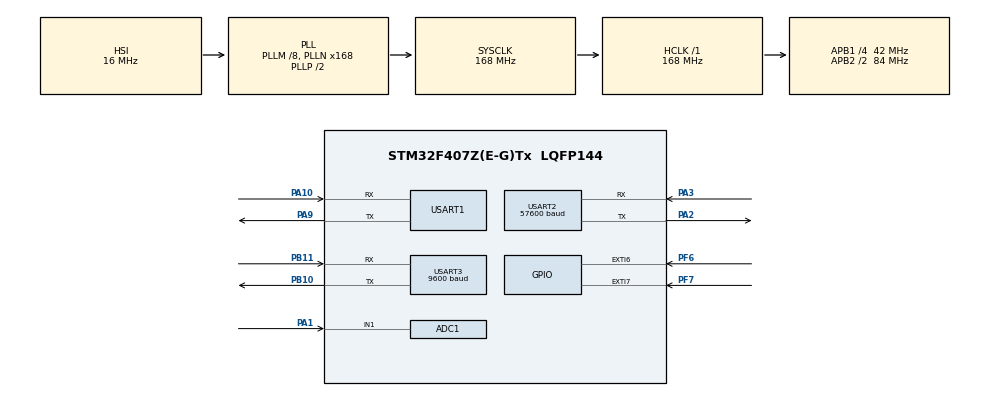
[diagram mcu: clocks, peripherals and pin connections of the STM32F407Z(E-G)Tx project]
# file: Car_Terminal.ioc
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ADC1.Channel-0\#ChannelRegularConversion=ADC_CHANNEL_1
ADC1.ClockPrescaler=ADC_CLOCK_SYNC_PCLK_DIV6
ADC1.NbrOfConversionFlag=1
ADC1.Rank-0\#ChannelRegularConversion=1
ADC1.SamplingTime-0\#ChannelRegularConversion=ADC_SAMPLETIME_3CYCLES
ADC1.master=1
Mcu.Family=STM32F4
Mcu.Name=STM32F407Z(E-G)Tx
Mcu.Package=LQFP144
NVIC.EXTI9_5_IRQn=true\:1\:0\:true\:false\:true\:true\:true\:true
NVIC.PriorityGroup=NVIC_PRIORITYGROUP_4
NVIC.RCC_IRQn=true\:0\:0\:false\:false\:true\:true\:false\:true
NVIC.TIM2_IRQn=true\:14\:0\:true\:false\:true\:true\:true\:true
PA1.Signal=ADCx_IN1
PA10.Mode=Asynchronous
PA10.Signal=USART1_RX
PA2.Mode=Asynchronous
PA2.Signal=USART2_TX
PA3.Mode=Asynchronous
PA3.Signal=USART2_RX
PA9.Mode=Asynchronous
PA9.Signal=USART1_TX
PB10.Mode=Asynchronous
PB10.Signal=USART3_TX
PB11.Mode=Asynchronous
PB11.Signal=USART3_RX
PF6.GPIO_ModeDefaultEXTI=GPIO_MODE_IT_FALLING
PF6.GPIO_PuPd=GPIO_PULLUP
PF6.Signal=GPXTI6
PF7.GPIO_ModeDefaultEXTI=GPIO_MODE_IT_RISING
PF7.GPIO_PuPd=GPIO_PULLDOWN
PF7.Signal=GPXTI7
ProjectManager.HeapSize=0x200
ProjectManager.StackSize=0x400
ProjectManager.TargetToolchain=MDK-ARM V5
RCC.48MHZClocksFreq_Value=84000000
RCC.AHBFreq_Value=168000000
RCC.APB1CLKDivider=RCC_HCLK_DIV4
RCC.APB1Freq_Value=42000000
RCC.APB1TimFreq_Value=84000000
RCC.APB2CLKDivider=RCC_HCLK_DIV2
RCC.APB2Freq_Value=84000000
RCC.APB2TimFreq_Value=168000000
RCC.CortexFreq_Value=168000000
RCC.HCLKFreq_Value=168000000
RCC.HSE_VALUE=25000000
RCC.HSI_VALUE=16000000
RCC.LSE_VALUE=32768
RCC.PLLM=8
RCC.PLLN=168
RCC.SYSCLKFreq_VALUE=168000000
RCC.SYSCLKSource=RCC_SYSCLKSOURCE_PLLCLK
RCC.VCOOutputFreq_Value=336000000
SH.ADCx_IN1.0=ADC1_IN1,IN1
TIM2.AutoReloadPreload=TIM_AUTORELOAD_PRELOAD_ENABLE
TIM2.ClockDivision=TIM_CLOCKDIVISION_DIV4
TIM2.CounterMode=TIM_COUNTERMODE_DOWN
TIM2.Period=2000
TIM2.Prescaler=42000
USART1.VirtualMode=VM_ASYNC
USART2.BaudRate=57600
USART2.VirtualMode=VM_ASYNC
USART3.BaudRate=9600
USART3.VirtualMode=VM_ASYNC
VP_TIM2_VS_ClockSourceINT.Mode=Internal
board=custom

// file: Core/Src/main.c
/* USER CODE BEGIN Header */
/**
  ******************************************************************************
  * @file           : main.c
  * @brief          : Main program body
  ******************************************************************************
  * @attention
  *
  * Copyright (c) 2024 STMicroelectronics.
  * All rights reserved.
  *
  * This software is licensed under terms that can be found in the LICENSE file
  * in the root directory of this software component.
  * If no LICENSE file comes with this software, it is provided AS-IS.
  *
  ******************************************************************************
  */
/* USER CODE END Header */
#include "main.h"
#include "adc.h"
#include "tim.h"
#include "usart.h"
#include "gpio.h"

/* USER CODE BEGIN Includes */
#include "MyCallbackFunc.h"
#include "string.h"
#include "AS608.h"
#include "AES128.h"
#include "syn6288.h"
/* USER CODE END Includes */

void SystemClock_Config(void);

/* USER CODE BEGIN 0 */

uint8_t SYN_StopCom[] = {0xFD, 0X00, 0X02, 0X02, 0XFD}; //停止合成
uint8_t SYN_SuspendCom[] = {0XFD, 0X00, 0X02, 0X03, 0XFC}; //暂停合成
uint8_t SYN_RecoverCom[] = {0XFD, 0X00, 0X02, 0X04, 0XFB}; //恢复合成
uint8_t SYN_ChackCom[] = {0XFD, 0X00, 0X02, 0X21, 0XDE}; //状濁查诿
uint8_t SYN_PowerDownCom[] = {0XFD, 0X00, 0X02, 0X88, 0X77}; //进入POWER DOWN 状濁命仿

/* USER CODE END 0 */

int main(void)
{
  /* USER CODE BEGIN 1 */

	//数据加密解密示例

//AES128_HANDLE AES128_Handle;
//	uint8_t DataBuff[64];//霿要加密的数据
//        uint8_t key[16];//钥匙key
//		uint32_t len;//加密的长庿
//				memset(key, 0, 16);//将key清零
//	key[0] = '1';//设置钥匙丿1其余全零
//        AES128_SetKey(&AES128_Handle, key);//AES128设置KEY，?过key获得对应的句柿
//	len = AES128_EncryptData(&AES128_Handle, DataBuff, 20);//通过句柄去去对数据进行加寿
//	AES128_DecryptData(&AES128_Handle, DataBuff, len);	//子操使:AES128解密128bit数据，len表示要解密数据的长度
  /* USER CODE END 1 */

  /* MCU Configuration--------------------------------------------------------*/

  /* Reset of all peripherals, Initializes the Flash interface and the Systick. */
  HAL_Init();

  /* Configure the system clock */
  SystemClock_Config();

  /* Initialize all configured peripherals */
  MX_GPIO_Init();
  MX_ADC1_Init();
  MX_TIM2_Init();
  MX_USART1_UART_Init();
  MX_USART2_UART_Init();
  MX_USART3_UART_Init();
  /* USER CODE BEGIN 2 */

	//选择背景音乐2?(0：无背景音乐  1-15：背景音乐可逿)
		//m[0~16]:0背景音乐为静音，16背景音乐音量朿夿
		//v[0~16]:0朗读音量为静音，16朗读音量朿夿
		//t[0~5]:0朗读语?最慢，5朗读语?最忿
		//其他不常用功能请参迃数据手冿
		//SYN_FrameInfo(2, "[v7][m1][t5]欢迎使用绿深旗舰店SYN6288语音合成模块");
		//暂停合成，此时没有用到，用于展示函数用法
		//YS_SYN_Set(SYN_SuspendCom);

  /* USER CODE END 2 */

  /* Infinite loop */
  while (1)
  {

    /* USER CODE BEGIN 3 */

		SYN_FrameInfo(2, "[v7][m1][t5]欢迎使用绿深旗舰店SYN6288语音合成模块");
		HAL_Delay(1500);
		HAL_Delay(1500);
		HAL_Delay(1500);
  }
  /* USER CODE END 3 */
}

void SystemClock_Config(void)
{
  RCC_OscInitTypeDef RCC_OscInitStruct = {0};
  RCC_ClkInitTypeDef RCC_ClkInitStruct = {0};

  /** Configure the main internal regulator output voltage
  */
  __HAL_RCC_PWR_CLK_ENABLE();
  __HAL_PWR_VOLTAGESCALING_CONFIG(PWR_REGULATOR_VOLTAGE_SCALE1);

  /** Initializes the RCC Oscillators according to the specified parameters
  * in the RCC_OscInitTypeDef structure.
  */
  RCC_OscInitStruct.OscillatorType = RCC_OSCILLATORTYPE_HSI;
  RCC_OscInitStruct.HSIState = RCC_HSI_ON;
  RCC_OscInitStruct.HSICalibrationValue = RCC_HSICALIBRATION_DEFAULT;
  RCC_OscInitStruct.PLL.PLLState = RCC_PLL_ON;
  RCC_OscInitStruct.PLL.PLLSource = RCC_PLLSOURCE_HSI;
  RCC_OscInitStruct.PLL.PLLM = 8;
  RCC_OscInitStruct.PLL.PLLN = 168;
  RCC_OscInitStruct.PLL.PLLP = RCC_PLLP_DIV2;
  RCC_OscInitStruct.PLL.PLLQ = 4;
  if (HAL_RCC_OscConfig(&RCC_OscInitStruct) != HAL_OK)
  {
    Error_Handler();
  }

  /** Initializes the CPU, AHB and APB buses clocks
  */
  RCC_ClkInitStruct.ClockType = RCC_CLOCKTYPE_HCLK|RCC_CLOCKTYPE_SYSCLK
                              |RCC_CLOCKTYPE_PCLK1|RCC_CLOCKTYPE_PCLK2;
  RCC_ClkInitStruct.SYSCLKSource = RCC_SYSCLKSOURCE_PLLCLK;
  RCC_ClkInitStruct.AHBCLKDivider = RCC_SYSCLK_DIV1;
  RCC_ClkInitStruct.APB1CLKDivider = RCC_HCLK_DIV4;
  RCC_ClkInitStruct.APB2CLKDivider = RCC_HCLK_DIV2;

  if (HAL_RCC_ClockConfig(&RCC_ClkInitStruct, FLASH_LATENCY_5) != HAL_OK)
  {
    Error_Handler();
  }
}

void Error_Handler(void)
{
  __disable_irq();
  while (1)
  {
  }
}
